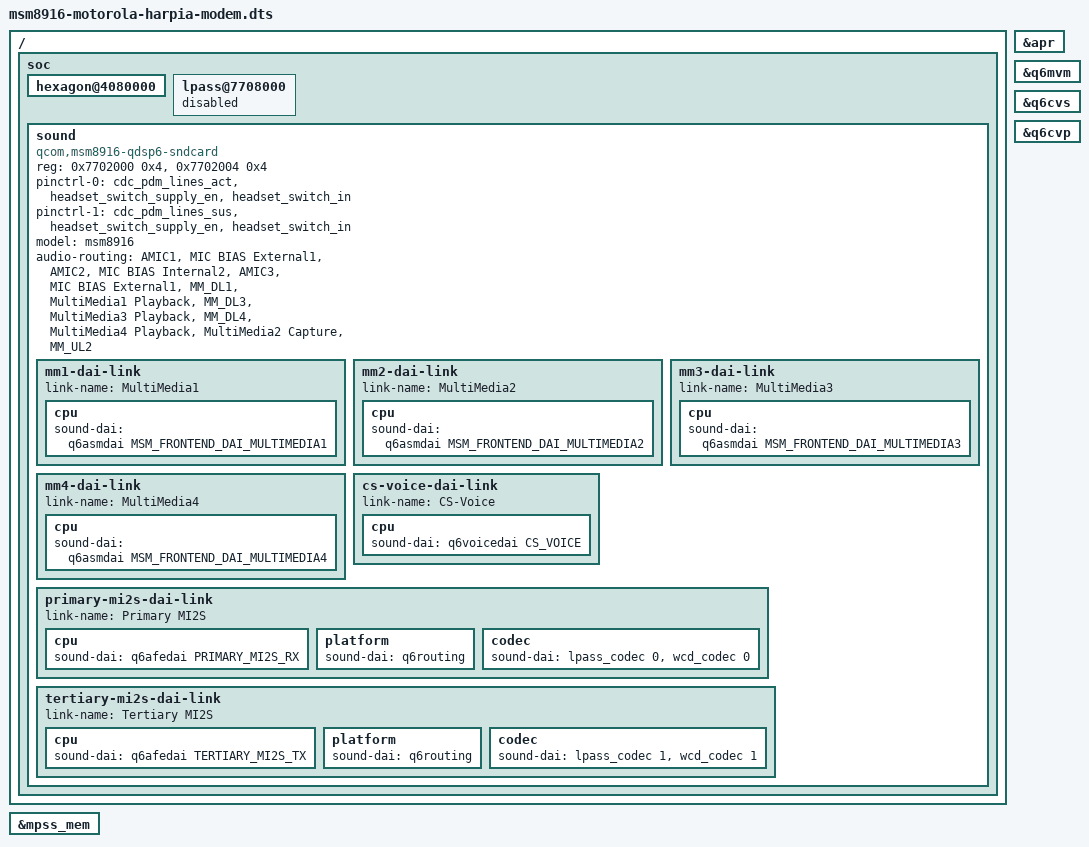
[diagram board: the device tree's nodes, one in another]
// SPDX-License-Identifier: GPL-2.0-only
#include "msm8916-motorola-harpia.dts"
#include <dt-bindings/sound/qcom,q6afe.h>
#include <dt-bindings/sound/qcom,q6asm.h>
#include <dt-bindings/sound/qcom,q6voice.h>

/ {
	soc {
		/delete-node/ sound;

		hexagon@4080000 {
			status = "okay";
		};

		lpass@7708000 {
			status = "disabled";
		};

		sound {
			compatible = "qcom,msm8916-qdsp6-sndcard";
			reg = <0x7702000 0x4>, <0x7702004 0x4>;
			reg-names = "mic-iomux", "spkr-iomux";

			pinctrl-names = "default", "sleep";
			pinctrl-0 = <&cdc_pdm_lines_act &headset_switch_supply_en
				     &headset_switch_in>;
			pinctrl-1 = <&cdc_pdm_lines_sus &headset_switch_supply_en
				     &headset_switch_in>;

			model = "msm8916";
			audio-routing =
				"AMIC1", "MIC BIAS External1",
				"AMIC2", "MIC BIAS Internal2",
				"AMIC3", "MIC BIAS External1",
				"MM_DL1", "MultiMedia1 Playback",
				"MM_DL3", "MultiMedia3 Playback",
				"MM_DL4", "MultiMedia4 Playback",
				"MultiMedia2 Capture", "MM_UL2";

			mm1-dai-link {
				link-name = "MultiMedia1";
				cpu {
					sound-dai = <&q6asmdai MSM_FRONTEND_DAI_MULTIMEDIA1>;
				};
			};

			mm2-dai-link {
				link-name = "MultiMedia2";
				cpu {
					sound-dai = <&q6asmdai MSM_FRONTEND_DAI_MULTIMEDIA2>;
				};
			};

			mm3-dai-link {
				link-name = "MultiMedia3";
				cpu {
					sound-dai = <&q6asmdai MSM_FRONTEND_DAI_MULTIMEDIA3>;
				};
			};

			mm4-dai-link {
				link-name = "MultiMedia4";
				cpu {
					sound-dai = <&q6asmdai MSM_FRONTEND_DAI_MULTIMEDIA4>;
				};
			};

			cs-voice-dai-link {
				link-name = "CS-Voice";
				cpu {
					sound-dai = <&q6voicedai CS_VOICE>;
				};
			};

			primary-mi2s-dai-link {
				link-name = "Primary MI2S";
				cpu {
					sound-dai = <&q6afedai PRIMARY_MI2S_RX>;
				};

				platform {
					sound-dai = <&q6routing>;
				};

				codec {
					sound-dai = <&lpass_codec 0>, <&wcd_codec 0>;
				};
			};

			tertiary-mi2s-dai-link {
				link-name = "Tertiary MI2S";
				cpu {
					sound-dai = <&q6afedai TERTIARY_MI2S_TX>;
				};

				platform {
					sound-dai = <&q6routing>;
				};

				codec {
					sound-dai = <&lpass_codec 1>, <&wcd_codec 1>;
				};
			};
		};
	};
};

&mpss_mem {
	status = "okay";
};

&apr {
	status = "okay";
};

&q6mvm {
	status = "okay";
};

&q6cvs {
	status = "okay";
};

&q6cvp {
	status = "okay";
};
